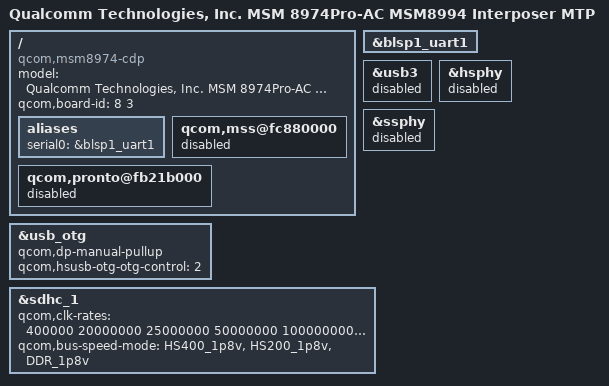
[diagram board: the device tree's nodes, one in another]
/* Copyright (c) 2013-2014, The Linux Foundation. All rights reserved.
 *
 * This program is free software; you can redistribute it and/or modify
 * it under the terms of the GNU General Public License version 2 and
 * only version 2 as published by the Free Software Foundation.
 *
 * This program is distributed in the hope that it will be useful,
 * but WITHOUT ANY WARRANTY; without even the implied warranty of
 * MERCHANTABILITY or FITNESS FOR A PARTICULAR PURPOSE.  See the
 * GNU General Public License for more details.
 */


/dts-v1/;

#include "msm8974pro-pm8994.dtsi"
#include "msm8994-mtp.dtsi"

/ {
	model = "Qualcomm Technologies, Inc. MSM 8974Pro-AC MSM8994 Interposer MTP";
	compatible = "qcom,msm8974-cdp", "qcom,msm8974", "qcom,mtp";
	qcom,board-id = <8 3>;

	aliases {
		serial0 = &blsp1_uart1;
	};

	qcom,mss@fc880000 {
		status = "disabled";
	};

	qcom,pronto@fb21b000 {
		status = "disabled";
	};
};

&blsp1_uart1 {
	status = "ok";
};

&usb_otg {
	qcom,dp-manual-pullup;
	qcom,hsusb-otg-otg-control = <2>;
	status = "ok";
};

&usb3 {
	status = "disabled";
};

&hsphy {
	status = "disabled";
};

&ssphy {
	status = "disabled";
};

&sdhc_1 {
	qcom,clk-rates = <400000 20000000 25000000 50000000 100000000 192000000 384000000>;
	qcom,bus-speed-mode = "HS400_1p8v", "HS200_1p8v", "DDR_1p8v";
};
